AUTOSAR XML (schema 00048)
package /ComponentTypes
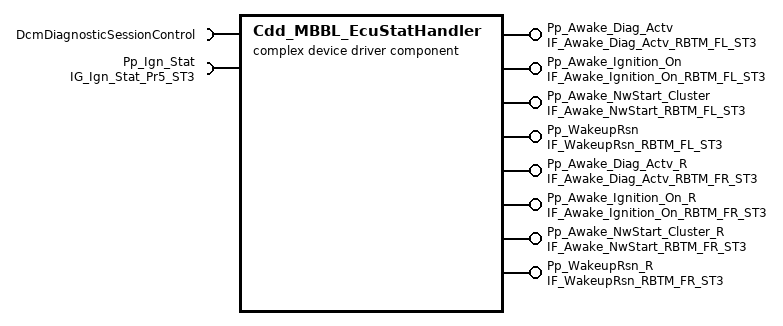
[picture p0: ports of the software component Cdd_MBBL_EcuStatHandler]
  complex device driver sw component type Cdd_MBBL_EcuStatHandler
    4 x provide port:
      Pp_Awake_Diag_Actv: nonqueued-sender-com-spec{data-element=Awake_Diag_Actv_RBTM_FL_ST3, init-value=0}, provided-interface=IF_Awake_Diag_Actv_RBTM_FL_ST3  # Awake_Diag_Actv_ECU4
      Pp_Awake_Ignition_On: nonqueued-sender-com-spec{data-element=Awake_Ignition_On_RBTM_FL_ST3, init-value=0}, provided-interface=IF_Awake_Ignition_On_RBTM_FL_ST3
      Pp_Awake_NwStart_Cluster: nonqueued-sender-com-spec{data-element=Awake_NwStart_RBTM_FL_ST3, init-value=0}, provided-interface=IF_Awake_NwStart_RBTM_FL_ST3  # Awake_NwStart_Cluster_ECU4
      Pp_WakeupRsn: nonqueued-sender-com-spec{data-element=WakeupRsn_RBTM_FL_ST3, init-value=constant-reference=XDIS_bggrcvuxyaw47ntt1npaw992u}, provided-interface=IF_WakeupRsn_RBTM_FL_ST3  # WakeupRsn_C04_ECU04
    require port DcmDiagnosticSessionControl: mode-switch-receiver-com-spec=DcmDiagnosticSessionControl, required-interface=DcmDiagnosticSessionControl
    require port Pp_Ign_Stat: nonqueued-receiver-com-spec{data-element=Ign_Stat_Pr5_ST3, filter=data-filter-type=ALWAYS, init-value=constant-reference=Const_Ign_Stat_InitVal}, required-interface=IG_Ign_Stat_Pr5_ST3  # Ignition state (degraded)
    4 x provide port:
      Pp_Awake_Diag_Actv_R: nonqueued-sender-com-spec{data-element=Awake_Diag_Actv_RBTM_FR_ST3, init-value=0}, provided-interface=IF_Awake_Diag_Actv_RBTM_FR_ST3
      Pp_Awake_Ignition_On_R: nonqueued-sender-com-spec{data-element=Awake_Ignition_On_RBTM_FR_ST3, init-value=0}, provided-interface=IF_Awake_Ignition_On_RBTM_FR_ST3
      Pp_Awake_NwStart_Cluster_R: nonqueued-sender-com-spec{data-element=Awake_NwStart_RBTM_FR_ST3, init-value=0}, provided-interface=IF_Awake_NwStart_RBTM_FR_ST3
      Pp_WakeupRsn_R: nonqueued-sender-com-spec{data-element=WakeupRsn_RBTM_FR_ST3, init-value=constant-reference=XDIS_bggrcvuxyaw47ntt1npaw992u}, provided-interface=IF_WakeupRsn_RBTM_FR_ST3
    behavior Cdd_MBBL_EcuStatHandler_InternalBehavior: data-type-mapping=[DATA_TYPE_MAPPING_SET, DataTypeMappings_DEV]
      ar-typed-per-instance-memorys:
        data NetworkRepeatMessageState: sw-calibration-access=READ-ONLY, type=uint32  # Bitmask which stores the repeat message state of all networks.
      init event Cdd_MBBL_EcuStatHandler_InitEvent: start-on-event=Cdd_MBBL_EcuStatHandler_Init
      swc mode switch event MST_DiagSessionChange_3: start-on-event=DiagSessionChange_EnterExtendedSession, activation=ON-ENTRY, mode=DcmDiagnosticSessionControl.DcmDiagnosticSessionControl.EXTENDED_SESSION
      swc mode switch event MST_DiagSessionChange_1: start-on-event=DiagSessionChange_ExitExtendedSession, activation=ON-EXIT, mode=DcmDiagnosticSessionControl.DcmDiagnosticSessionControl.EXTENDED_SESSION
      4 x runnable:
        Cdd_MBBL_EcuStatHandler_Init: mode-access-point=DcmDiagnosticSessionControl.DcmDiagnosticSessionControl  # ------------------------------------------------------------------------------------- This init runnable checks all EcuM wakeup sources and sets the wakeup reason of the EcuStat message. This includes validated wakeup sources as well as wakeup sources with pending validation. As this is done by calling an EcuM-API directly this component is considered a CDD. Since multiple wakeup reasons can be active at the same time but the EcuStat message allows for only one valid wakeup reason the priority of said reasons can be changed by shifting the if-blocks around in the implementation. -------------------------------------------------------------------------------------
          data-receive-point-by-arguments:
            access REC_Pp_Ign_Stat_Ign_Stat_Pr5_ST3: accessed-variable=Pp_Ign_Stat.Ign_Stat_Pr5_ST3
          data-send-points:
            6 x access:
              SEND_Pp_Awake_Diag_Actv_Awake_Diag_Actv_RBTM_FL_ST3: accessed-variable=Pp_Awake_Diag_Actv.Awake_Diag_Actv_RBTM_FL_ST3
              SEND_Pp_Awake_Ignition_On_Awake_Ignition_On_RBTM_FL_ST3: accessed-variable=Pp_Awake_Ignition_On.Awake_Ignition_On_RBTM_FL_ST3
              SEND_Pp_WakeupRsn_WakeupRsn_RBTM_FL_ST3: accessed-variable=Pp_WakeupRsn.WakeupRsn_RBTM_FL_ST3
              SEND_Pp_Awake_Diag_Actv_R_Awake_Diag_Actv_RBTM_FR_ST3: accessed-variable=Pp_Awake_Diag_Actv_R.Awake_Diag_Actv_RBTM_FR_ST3
              SEND_Pp_Awake_Ignition_On_R_Awake_Ignition_On_RBTM_FR_ST3: accessed-variable=Pp_Awake_Ignition_On_R.Awake_Ignition_On_RBTM_FR_ST3
              SEND_Pp_WakeupRsn_R_WakeupRsn_RBTM_FR_ST3: accessed-variable=Pp_WakeupRsn_R.WakeupRsn_RBTM_FR_ST3
        DiagSessionChange_EnterExtendedSession  # ------------------------------------------------------------------------------------- This runnable is executed when the ECU enters the extended diagnostic session state. It activates the awake reason Awake_Diag_Actv (MSS 20200-396). -------------------------------------------------------------------------------------
          data-send-points:
            access SEND_Pp_Awake_Diag_Actv_Awake_Diag_Actv_RBTM_FL_ST3: accessed-variable=Pp_Awake_Diag_Actv.Awake_Diag_Actv_RBTM_FL_ST3
            access SEND_Pp_Awake_Diag_Actv_R_Awake_Diag_Actv_RBTM_FR_ST3: accessed-variable=Pp_Awake_Diag_Actv_R.Awake_Diag_Actv_RBTM_FR_ST3
        DiagSessionChange_ExitExtendedSession  # ------------------------------------------------------------------------------------- This runnable is executed when the ECU exits the extended diagnostic session state. It deactivates the awake reason Awake_Diag_Actv (MSS 20200-396). -------------------------------------------------------------------------------------
          data-send-points:
            access SEND_Pp_Awake_Diag_Actv_Awake_Diag_Actv_RBTM_FL_ST3: accessed-variable=Pp_Awake_Diag_Actv.Awake_Diag_Actv_RBTM_FL_ST3
            access SEND_Pp_Awake_Diag_Actv_R_Awake_Diag_Actv_RBTM_FR_ST3: accessed-variable=Pp_Awake_Diag_Actv_R.Awake_Diag_Actv_RBTM_FR_ST3
        NmStateChange  # ------------------------------------------------------------------------------------- This runnable is called in the context of the NM state indication (NmAppl_StateChangeInd). For this reason there is no trigger configured and this component is considered a CDD. It writes the state of the awake reason Awake_NwSt based on the NM state (MSS 20200-396). The awake reason will remain active as long as there is at least one network which is still in the repeat message state. As this is implemented using a bitmask this functionality is currently limited to 32 channels. -------------------------------------------------------------------------------------
          data-send-points:
            access SEND_Pp_Awake_NwStart_Cluster_Awake_NwStart_RBTM_FL_ST3: accessed-variable=Pp_Awake_NwStart_Cluster.Awake_NwStart_RBTM_FL_ST3
            access SEND_Pp_Awake_NwStart_Cluster_R_Awake_NwStart_RBTM_FR_ST3: accessed-variable=Pp_Awake_NwStart_Cluster_R.Awake_NwStart_RBTM_FR_ST3
  swc implementation Cdd_MBBL_EcuStatHandler_Implementation: behavior=Cdd_MBBL_EcuStatHandler_InternalBehavior
    code-descriptors:
      code Default: artifact-descriptors=autosar-engineering-object=category=SWSRC
